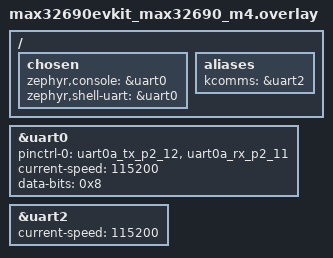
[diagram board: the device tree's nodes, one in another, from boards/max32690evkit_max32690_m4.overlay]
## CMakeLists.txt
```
# Copyright (c) 2023-2025 Antmicro <www.antmicro.com>
#
# SPDX-License-Identifier: Apache-2.0

cmake_minimum_required(VERSION 3.13.1)

# adds possibility to increase simulated board memory
include(../cmake/increase_board_memory.cmake)
kenning_increase_board_memory()

find_package(Zephyr REQUIRED HINTS $ENV{ZEPHYR_BASE})

project(app LANGUAGES C)

kenning_add_board_repl_target()

target_sources(app PRIVATE src/main.c)
```

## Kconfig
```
# Copyright (c) 2023-2024 Antmicro <www.antmicro.com>
#
# SPDX-License-Identifier: Apache-2.0

menu "Zephyr"
source "Kconfig.zephyr"
endmenu

module = APP
module-str = app
source "subsys/logging/Kconfig.template.log_config"
```

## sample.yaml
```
# Copyright (c) 2023-2024 Antmicro <www.antmicro.com>
#
# SPDX-License-Identifier: Apache-2.0

sample:
  description: Kenning Zephyr runtime
  name: kenning-zephyr-runtime
common:
  build_only: true
  integration_platforms:
    - nrf52840dk_52840
tests:
  app.default: {}
  app.debug:
    extra_overlay_confs:
      - debug.conf
```

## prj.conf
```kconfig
# Copyright (c) 2023-2025 Antmicro <www.antmicro.com>
#
# SPDX-License-Identifier: Apache-2.0

CONFIG_KENNING_INFERENCE_LIB=y
CONFIG_KENNING_ML_RUNTIME_STUB=y
CONFIG_KENNING_COMMUNICATION_PROTOCOL_UART=y
CONFIG_KENNING_SEND_LOGS=y

CONFIG_SERIAL=y
CONFIG_FPU=y

CONFIG_LOG=y
CONFIG_LOG_MODE_IMMEDIATE=y
CONFIG_LOG_SIMPLE_MSG_OPTIMIZE=y
CONFIG_LOG_DEFAULT_LEVEL=3
CONFIG_LOG_MAX_LEVEL=3
CONFIG_APP_LOG_LEVEL_DBG=n

CONFIG_CALLBACKS_LOG_LEVEL_DBG=y
CONFIG_INFERENCE_SERVER_LOG_LEVEL_DBG=y
CONFIG_KENNING_PROTOCOL_LOG_LEVEL_DBG=y
CONFIG_MODEL_LOG_LEVEL_DBG=y
CONFIG_RUNTIME_WRAPPER_LOG_LEVEL_DBG=y
CONFIG_UART_LOG_LEVEL_DBG=y
```

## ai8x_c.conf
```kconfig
# Copyright (c) 2025 Antmicro <www.antmicro.com>
#
# SPDX-License-Identifier: Apache-2.0

CONFIG_KENNING_ML_RUNTIME_AI8X=y

CONFIG_CLOCK_CONTROL=y
CONFIG_NEWLIB_LIBC=y
CONFIG_NEWLIB_LIBC_NANO=y
```

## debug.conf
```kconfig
# Copyright (c) 2023-2024 Antmicro <www.antmicro.com>
#
# SPDX-License-Identifier: Apache-2.0

# compiler
CONFIG_DEBUG_OPTIMIZATIONS=y

# console
CONFIG_CONSOLE=y

# UART console
CONFIG_SERIAL=y
CONFIG_UART_CONSOLE=y

# logging
CONFIG_LOG=y
CONFIG_APP_LOG_LEVEL_DBG=y
CONFIG_NEWLIB_LIBC=y
CONFIG_NEWLIB_LIBC_NANO=y
```

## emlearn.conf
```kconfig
CONFIG_KENNING_ML_RUNTIME_EMLEARN=y
```

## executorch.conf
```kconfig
# Copyright (c) 2025 Antmicro <www.antmicro.com>
#
# SPDX-License-Identifier: Apache-2.0

CONFIG_KENNING_ML_RUNTIME_EXECUTORCH=y

CONFIG_REQUIRES_FULL_LIBCPP=y
CONFIG_CPP=y
CONFIG_STD_C17=y
CONFIG_STD_CPP17=y

CONFIG_REQUIRES_FLOAT_PRINTF=y
CONFIG_ARM_MMU=n

CONFIG_MAIN_STACK_SIZE=24000
CONFIG_HEAP_MEM_POOL_SIZE=30000

CONFIG_BOOT_BANNER=n
CONFIG_PRINTK=n
CONFIG_LOG_BACKEND_UART=n
```

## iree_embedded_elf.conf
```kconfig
# Copyright (c) 2023-2025 Antmicro <www.antmicro.com>
#
# SPDX-License-Identifier: Apache-2.0

CONFIG_KENNING_ML_RUNTIME_IREE=y
CONFIG_KENNING_IREE_LOADER_EMBEDDED_ELF=y

CONFIG_CPP=y
CONFIG_STD_C17=y
CONFIG_STD_CPP20=y
CONFIG_GNU_C_EXTENSIONS=y
CONFIG_REQUIRES_FLOAT_PRINTF=y
CONFIG_POSIX_API=y
CONFIG_REQUIRES_FULL_LIBCPP=y
CONFIG_MAIN_STACK_SIZE=16000
CONFIG_TIMING_FUNCTIONS=y

CONFIG_KENNING_IREE_MODEL_BUFFER_SIZE=60
CONFIG_KENNING_IREE_HEAP_SIZE=350
```

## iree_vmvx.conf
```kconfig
# Copyright (c) 2023-2025 Antmicro <www.antmicro.com>
#
# SPDX-License-Identifier: Apache-2.0

CONFIG_KENNING_ML_RUNTIME_IREE=y
CONFIG_KENNING_IREE_LOADER_VMVX=y

CONFIG_CPP=y
CONFIG_STD_C17=y
CONFIG_STD_CPP20=y
CONFIG_GNU_C_EXTENSIONS=y
CONFIG_POSIX_AEP_CHOICE_BASE=y
CONFIG_REQUIRES_FLOAT_PRINTF=y
CONFIG_REQUIRES_FULL_LIBCPP=y
CONFIG_MAIN_STACK_SIZE=16000

CONFIG_KENNING_IREE_MODEL_BUFFER_SIZE=60
CONFIG_KENNING_IREE_HEAP_SIZE=160
```

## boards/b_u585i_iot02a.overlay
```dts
/ {
    aliases {
        kcomms = &uart4;
    };
};
```

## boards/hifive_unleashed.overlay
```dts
/ {
    aliases {
        kcomms = &uart0;
    };
};
```

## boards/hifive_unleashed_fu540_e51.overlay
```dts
&uart1 {
    status = "okay";
    current-speed = <115200>;
};

/ {
    aliases {
        kcomms = &uart1;
    };
};
```

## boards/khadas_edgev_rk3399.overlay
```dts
/ {
    aliases {
        kcomms = &uart2;
    };
};
```

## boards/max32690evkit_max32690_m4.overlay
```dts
&uart0 {
    status = "okay";
    pinctrl-0 = < &uart0a_tx_p2_12 &uart0a_rx_p2_11 >;
    pinctrl-names = "default";
    current-speed = < 115200 >;
    data-bits = < 0x8 >;
};

&uart2 {
    current-speed = < 115200 >;
};

/ {
    chosen {
        zephyr,console = &uart0;
        zephyr,shell-uart = &uart0;
    };
    aliases {
        kcomms = &uart2;
    };
};
```

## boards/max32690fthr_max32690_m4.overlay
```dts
&uart0 {
    current-speed = < 9600 >;
};

&uart2 {
    current-speed = < 9600 >;
};

/ {
    aliases {
        kcomms = &uart2;
    };
};
```

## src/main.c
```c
/*
 * Copyright (c) 2023-2025 Antmicro <www.antmicro.com>
 *
 * SPDX-License-Identifier: Apache-2.0
 */

#include "kenning_inference_lib/core/inference_server.h"
#include "kenning_inference_lib/core/utils.h"
#include <zephyr/logging/log.h>

LOG_MODULE_REGISTER(app, CONFIG_APP_LOG_LEVEL);

ZPL_CODE_SCOPE_DEFINE(client_request,
#ifdef CONFIG_KENNING_ZEPHELIN_TRACE_REQUESTS
                      true
#else
                      false
#endif
);

int main(void)
{
    if (STATUS_OK != init_server())
    {
        LOG_ERR("Server init failed");
        return 1;
    }
    // main runtime loop
    while (1)
    {
        ZPL_MARK_CODE_SCOPE(client_request)
        {
            protocol_event_t event;
            if (STATUS_OK == wait_for_protocol_event(&event))
            {
                handle_protocol_event(&event);
            }
        }
    }
    return 0;
}
```
